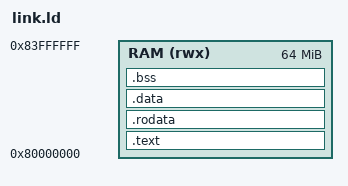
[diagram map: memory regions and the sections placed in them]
ENTRY(_start)
MEMORY { RAM (rwx) : ORIGIN = 0x80000000, LENGTH = 64M }
SECTIONS {
  .text : { *(.text._start) *(.text*) } > RAM
  .rodata : { *(.rodata*) } > RAM
  .data : { *(.data*) *(.sdata*) } > RAM
  .bss : { *(.bss*) *(.sbss*) *(COMMON) } > RAM
  _stack_top = ORIGIN(RAM) + LENGTH(RAM);
}
